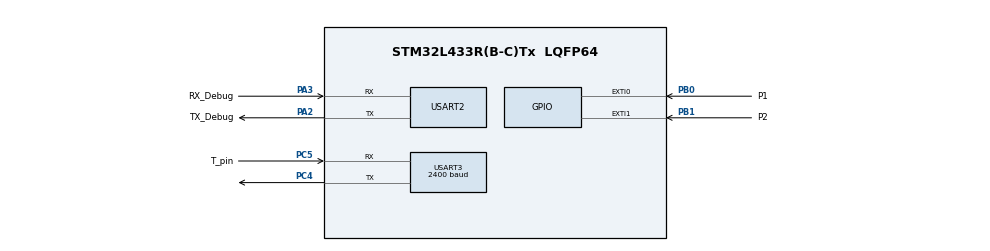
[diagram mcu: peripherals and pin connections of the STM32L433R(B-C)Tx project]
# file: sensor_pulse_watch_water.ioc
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Mcu.Family=STM32L4
Mcu.Name=STM32L433R(B-C)Tx
Mcu.Package=LQFP64
NVIC.EXTI0_IRQn=true\:0\:0\:false\:false\:true\:true\:true\:true
NVIC.EXTI1_IRQn=true\:0\:0\:false\:false\:true\:true\:true\:true
NVIC.PriorityGroup=NVIC_PRIORITYGROUP_4
NVIC.USART2_IRQn=true\:1\:0\:true\:false\:true\:true\:true\:true
PA13\ (JTMS-SWDIO).Mode=Serial_Wire
PA13\ (JTMS-SWDIO).Signal=SYS_JTMS-SWDIO
PA14\ (JTCK-SWCLK).Mode=Serial_Wire
PA14\ (JTCK-SWCLK).Signal=SYS_JTCK-SWCLK
PA2.GPIO_Label=TX_Debug
PA2.Mode=Asynchronous
PA2.Signal=USART2_TX
PA3.GPIO_Label=RX_Debug
PA3.Mode=Asynchronous
PA3.Signal=USART2_RX
PB0.GPIO_Label=P1
PB0.GPIO_PuPd=GPIO_PULLUP
PB0.Signal=GPXTI0
PB1.GPIO_Label=P2
PB1.Signal=GPXTI1
PC4.Mode=Asynchronous
PC4.Signal=USART3_TX
PC5.GPIO_Label=T_pin
PC5.Mode=Asynchronous
PC5.Signal=USART3_RX
ProjectManager.HeapSize=0x200
ProjectManager.StackSize=0x400
ProjectManager.TargetToolchain=EWARM V8.32
RCC.HSE_VALUE=8000000
RCC.HSI48_VALUE=48000000
RCC.HSI_VALUE=16000000
RCC.LSE_VALUE=32768
RCC.MSI_VALUE=4000000
RCC.VCOOutputFreq_Value=32000000
USART2.VirtualMode-Asynchronous=VM_ASYNC
USART3.BaudRate=2400
USART3.VirtualMode-Asynchronous=VM_ASYNC
board=custom

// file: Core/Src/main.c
/* USER CODE BEGIN Header */
/**
  ******************************************************************************
  * @file           : main.c
  * @brief          : Main program body
  ******************************************************************************
  * @attention
  *
  * Copyright (c) 2026 STMicroelectronics.
  * All rights reserved.
  *
  * This software is licensed under terms that can be found in the LICENSE file
  * in the root directory of this software component.
  * If no LICENSE file comes with this software, it is provided AS-IS.
  *
  ******************************************************************************
  */
/* USER CODE END Header */
#include "main.h"

/* USER CODE BEGIN Includes */
#include "app_sensor.h"
#include "debug_uart.h"
/* USER CODE END Includes */

UART_HandleTypeDef huart2;
UART_HandleTypeDef huart3;

void SystemClock_Config(void);
static void MX_GPIO_Init(void);
static void MX_USART2_UART_Init(void);
static void MX_USART3_UART_Init(void);

int main(void)
{

  /* MCU Configuration--------------------------------------------------------*/

  /* Reset of all peripherals, Initializes the Flash interface and the Systick. */
  HAL_Init();

  /* Configure the system clock */
  SystemClock_Config();

  /* Initialize all configured peripherals */
  MX_GPIO_Init();
  MX_USART2_UART_Init();
  MX_USART3_UART_Init();
  /* USER CODE BEGIN 2 */
 if (AppSensor_Init(&huart3, &huart2) != HAL_OK)
{
  Error_Handler();
}
  /* USER CODE END 2 */

  /* Infinite loop */
  while (1)
  {
    /* USER CODE BEGIN 3 */
    AppSensor_Task();

  }
  /* USER CODE END 3 */
}

void SystemClock_Config(void)
{
  RCC_OscInitTypeDef RCC_OscInitStruct = {0};
  RCC_ClkInitTypeDef RCC_ClkInitStruct = {0};

  /** Configure the main internal regulator output voltage
  */
  if (HAL_PWREx_ControlVoltageScaling(PWR_REGULATOR_VOLTAGE_SCALE1) != HAL_OK)
  {
    Error_Handler();
  }

  /** Initializes the RCC Oscillators according to the specified parameters
  * in the RCC_OscInitTypeDef structure.
  */
  RCC_OscInitStruct.OscillatorType = RCC_OSCILLATORTYPE_MSI;
  RCC_OscInitStruct.MSIState = RCC_MSI_ON;
  RCC_OscInitStruct.MSICalibrationValue = 0;
  RCC_OscInitStruct.MSIClockRange = RCC_MSIRANGE_6;
  RCC_OscInitStruct.PLL.PLLState = RCC_PLL_NONE;
  if (HAL_RCC_OscConfig(&RCC_OscInitStruct) != HAL_OK)
  {
    Error_Handler();
  }

  /** Initializes the CPU, AHB and APB buses clocks
  */
  RCC_ClkInitStruct.ClockType = RCC_CLOCKTYPE_HCLK|RCC_CLOCKTYPE_SYSCLK
                              |RCC_CLOCKTYPE_PCLK1|RCC_CLOCKTYPE_PCLK2;
  RCC_ClkInitStruct.SYSCLKSource = RCC_SYSCLKSOURCE_MSI;
  RCC_ClkInitStruct.AHBCLKDivider = RCC_SYSCLK_DIV1;
  RCC_ClkInitStruct.APB1CLKDivider = RCC_HCLK_DIV1;
  RCC_ClkInitStruct.APB2CLKDivider = RCC_HCLK_DIV1;

  if (HAL_RCC_ClockConfig(&RCC_ClkInitStruct, FLASH_LATENCY_0) != HAL_OK)
  {
    Error_Handler();
  }
}

static void MX_USART2_UART_Init(void)
{

  huart2.Instance = USART2;
  huart2.Init.BaudRate = 115200;
  huart2.Init.WordLength = UART_WORDLENGTH_8B;
  huart2.Init.StopBits = UART_STOPBITS_1;
  huart2.Init.Parity = UART_PARITY_NONE;
  huart2.Init.Mode = UART_MODE_TX_RX;
  huart2.Init.HwFlowCtl = UART_HWCONTROL_NONE;
  huart2.Init.OverSampling = UART_OVERSAMPLING_16;
  huart2.Init.OneBitSampling = UART_ONE_BIT_SAMPLE_DISABLE;
  huart2.AdvancedInit.AdvFeatureInit = UART_ADVFEATURE_NO_INIT;
  if (HAL_UART_Init(&huart2) != HAL_OK)
  {
    Error_Handler();
  }

}

static void MX_USART3_UART_Init(void)
{

  huart3.Instance = USART3;
  huart3.Init.BaudRate = 2400;
  huart3.Init.WordLength = UART_WORDLENGTH_8B;
  huart3.Init.StopBits = UART_STOPBITS_1;
  huart3.Init.Parity = UART_PARITY_NONE;
  huart3.Init.Mode = UART_MODE_TX_RX;
  huart3.Init.HwFlowCtl = UART_HWCONTROL_NONE;
  huart3.Init.OverSampling = UART_OVERSAMPLING_16;
  huart3.Init.OneBitSampling = UART_ONE_BIT_SAMPLE_DISABLE;
  huart3.AdvancedInit.AdvFeatureInit = UART_ADVFEATURE_NO_INIT;
  if (HAL_UART_Init(&huart3) != HAL_OK)
  {
    Error_Handler();
  }

}

static void MX_GPIO_Init(void)
{
  GPIO_InitTypeDef GPIO_InitStruct = {0};

  /* GPIO Ports Clock Enable */
  __HAL_RCC_GPIOA_CLK_ENABLE();
  __HAL_RCC_GPIOC_CLK_ENABLE();
  __HAL_RCC_GPIOB_CLK_ENABLE();

  /*Configure GPIO pin : P1_Pin */
  GPIO_InitStruct.Pin = P1_Pin;
  GPIO_InitStruct.Mode = GPIO_MODE_IT_RISING;
  GPIO_InitStruct.Pull = GPIO_PULLUP;
  HAL_GPIO_Init(P1_GPIO_Port, &GPIO_InitStruct);

  /*Configure GPIO pin : P2_Pin */
  GPIO_InitStruct.Pin = P2_Pin;
  GPIO_InitStruct.Mode = GPIO_MODE_IT_RISING;
  GPIO_InitStruct.Pull = GPIO_NOPULL;
  HAL_GPIO_Init(P2_GPIO_Port, &GPIO_InitStruct);

  /* EXTI interrupt init*/
  HAL_NVIC_SetPriority(EXTI0_IRQn, 0, 0);
  HAL_NVIC_EnableIRQ(EXTI0_IRQn);

  HAL_NVIC_SetPriority(EXTI1_IRQn, 0, 0);
  HAL_NVIC_EnableIRQ(EXTI1_IRQn);

}

void Error_Handler(void)
{
  __disable_irq();
  while (1)
  {
  }
}
